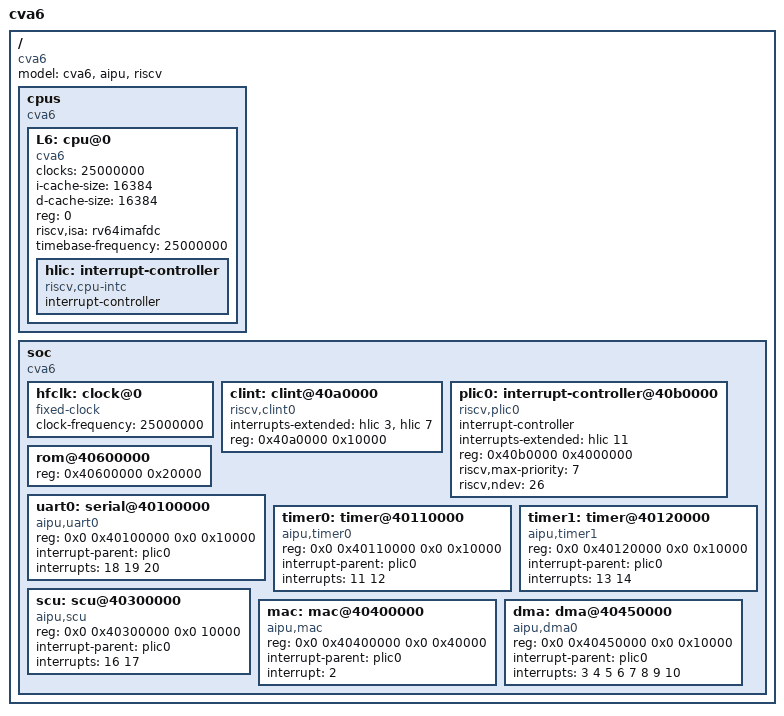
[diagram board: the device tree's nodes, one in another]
/dts-v1/;
/ {
        #address-cells = <2>;
        #size-cells = <2>;
        compatible = "cva6","aipu","riscv";
        model = "cva6","aipu","riscv";
        cpus {
                #address-cells = <1>;
                #size-cells = <0>;
                compatible = "cva6","riscv";
                L6: cpu@0 {
                        clocks = <25000000>;
                        compatible = "cva6", "riscv";
                        device_type = "cpu";
                        i-cache-size = <16384>;
                        d-cache-size = <16384>;
                        reg = <0>;
                        riscv,isa = "rv64imafdc";
                        status = "okay";
                        timebase-frequency = <25000000>;
                        hlic: interrupt-controller {
                                #interrupt-cells = <1>;
                                compatible = "riscv,cpu-intc";
                                interrupt-controller;
                        };
                };
        };
        soc {
                #address-cells = <1>;
                #size-cells = <1>;
                #clock-cells = <1>;
                compatible = "cva6","aipu";
                ranges;
                hfclk: clock@0 {
                        #clock-cells = <0>;
                        compatible = "fixed-clock";
                        clock-frequency = <25000000>;
                };
                clint: clint@40a0000 {
                        compatible = "riscv,clint0";
                        interrupts-extended = <&hlic 3 &hlic 7>;
                        reg = <0x40a0000 0x10000>;
                        reg-names = "control";
                };
                plic0: interrupt-controller@40b0000 {
                        #interrupt-cells = <1>;
                        compatible = "riscv,plic0";
                        interrupt-controller;
                        interrupts-extended = <&hlic 11>;
                        reg = <0x40b0000 0x4000000>;
                        reg-names = "control";
                        riscv,max-priority = <7>;
                        riscv,ndev = <26>;
                };
                rom@40600000 {
                        reg = <0x40600000 0x20000>;
                        reg-names = "mem";
                };
                uart0: serial@40100000 {
                    compatible = "aipu,uart0";
                    reg = <0x0 0x40100000 0x0 0x10000>;
                    interrupt-parent = <&plic0>;
                    interrupts = <18 19 20>;
                    status = "okay";
                    };
                timer0: timer@40110000 {
                    compatible = "aipu,timer0";
                    reg = <0x0 0x40110000 0x0 0x10000>;
                    interrupt-parent = <&plic0>;
                    interrupts = <11 12>;
                    status = "okay";
                };
                timer1: timer@40120000 {
                    compatible = "aipu,timer1";
                    reg = <0x0 0x40120000 0x0 0x10000>;
                    interrupt-parent = <&plic0>;
                    interrupts = <13 14>;
                    status = "okay";
                };
                scu: scu@40300000 {
                    compatible = "aipu,scu";
                    reg = <0x0 0x40300000 0x0 10000>;
                    interrupt-parent = <&plic0>;
                    interrupts = <16 17>;
                    status = "okay";
                };
                mac: mac@40400000 {
                    compatible = "aipu,mac";
                    reg = <0x0 0x40400000 0x0 0x40000>;
                    interrupt-parent = <&plic0>;
                    interrupt = <2>;
                    status = "okay";
                };
                dma: dma@40450000 {
                    compatible = "aipu,dma0";
                    reg = <0x0 0x40450000 0x0 0x10000>;
                    interrupt-parent = <&plic0>;
                    interrupts = <3 4 5 6 7 8 9 10>;
                    #dma-cells = <1>;
                };
        };
};
